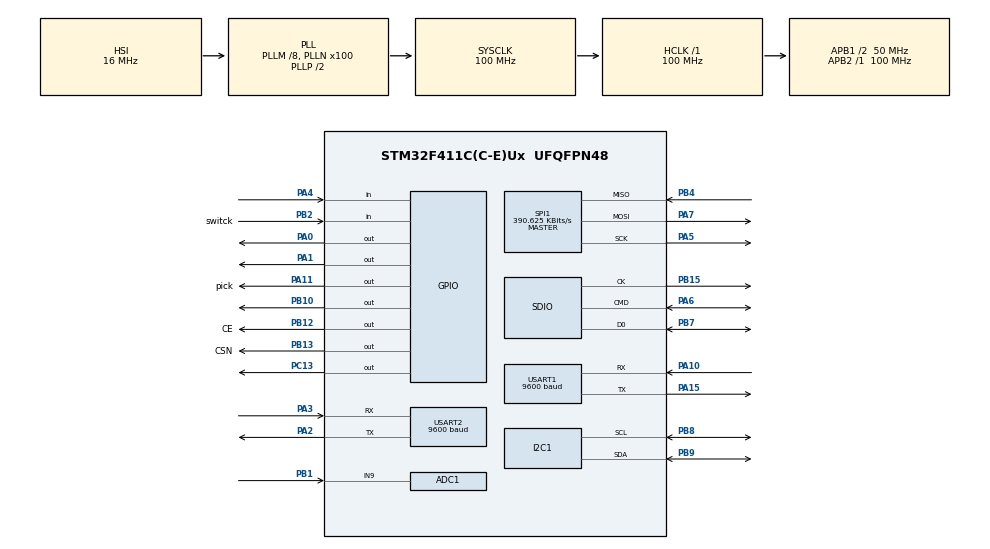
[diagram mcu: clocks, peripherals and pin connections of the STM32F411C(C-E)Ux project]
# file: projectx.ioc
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ADC1.Channel-2\#ChannelRegularConversion=ADC_CHANNEL_9
ADC1.NbrOfConversionFlag=1
ADC1.Rank-2\#ChannelRegularConversion=1
ADC1.SamplingTime-2\#ChannelRegularConversion=ADC_SAMPLETIME_3CYCLES
ADC1.master=1
Dma.Request0=SDIO_RX
Dma.Request1=SDIO_TX
Dma.SDIO_RX.0.Direction=DMA_PERIPH_TO_MEMORY
Dma.SDIO_RX.0.FIFOMode=DMA_FIFOMODE_ENABLE
Dma.SDIO_RX.0.FIFOThreshold=DMA_FIFO_THRESHOLD_FULL
Dma.SDIO_RX.0.Instance=DMA2_Stream3
Dma.SDIO_RX.0.MemBurst=DMA_MBURST_INC4
Dma.SDIO_RX.0.MemDataAlignment=DMA_MDATAALIGN_WORD
Dma.SDIO_RX.0.MemInc=DMA_MINC_ENABLE
Dma.SDIO_RX.0.Mode=DMA_PFCTRL
Dma.SDIO_RX.0.PeriphBurst=DMA_PBURST_INC4
Dma.SDIO_RX.0.PeriphDataAlignment=DMA_PDATAALIGN_WORD
Dma.SDIO_RX.0.PeriphInc=DMA_PINC_DISABLE
Dma.SDIO_RX.0.Priority=DMA_PRIORITY_LOW
Dma.SDIO_TX.1.Direction=DMA_MEMORY_TO_PERIPH
Dma.SDIO_TX.1.FIFOMode=DMA_FIFOMODE_ENABLE
Dma.SDIO_TX.1.FIFOThreshold=DMA_FIFO_THRESHOLD_FULL
Dma.SDIO_TX.1.Instance=DMA2_Stream6
Dma.SDIO_TX.1.MemBurst=DMA_MBURST_INC4
Dma.SDIO_TX.1.MemDataAlignment=DMA_MDATAALIGN_WORD
Dma.SDIO_TX.1.MemInc=DMA_MINC_ENABLE
Dma.SDIO_TX.1.Mode=DMA_PFCTRL
Dma.SDIO_TX.1.PeriphBurst=DMA_PBURST_INC4
Dma.SDIO_TX.1.PeriphDataAlignment=DMA_PDATAALIGN_WORD
Dma.SDIO_TX.1.PeriphInc=DMA_PINC_DISABLE
Dma.SDIO_TX.1.Priority=DMA_PRIORITY_LOW
FATFS._MAX_SS=4096
FATFS._USE_LFN=1
Mcu.Family=STM32F4
Mcu.Name=STM32F411C(C-E)Ux
Mcu.Package=UFQFPN48
NVIC.DMA2_Stream3_IRQn=true\:0\:0\:false\:false\:true\:false\:true\:true
NVIC.DMA2_Stream6_IRQn=true\:0\:0\:false\:false\:true\:false\:true\:true
NVIC.PriorityGroup=NVIC_PRIORITYGROUP_4
NVIC.USART1_IRQn=true\:0\:0\:false\:false\:true\:true\:false\:true
PA0-WKUP.Signal=GPIO_Output
PA1.Signal=GPIO_Output
PA10.Mode=Asynchronous
PA10.Signal=USART1_RX
PA11.GPIO_Label=pick
PA11.Signal=GPIO_Output
PA13.Mode=Serial_Wire
PA13.Signal=SYS_JTMS-SWDIO
PA14.Mode=Serial_Wire
PA14.Signal=SYS_JTCK-SWCLK
PA15.Mode=Asynchronous
PA15.Signal=USART1_TX
PA2.Mode=Asynchronous
PA2.Signal=USART2_TX
PA3.Mode=Asynchronous
PA3.Signal=USART2_RX
PA4.Signal=GPIO_Input
PA5.Mode=Full_Duplex_Master
PA5.Signal=SPI1_SCK
PA6.Mode=SD_1_bit
PA6.Signal=SDIO_CMD
PA7.Mode=Full_Duplex_Master
PA7.Signal=SPI1_MOSI
PB1.Signal=ADCx_IN9
PB10.Signal=GPIO_Output
PB12.GPIO_Label=CE
PB12.Signal=GPIO_Output
PB13.GPIO_Label=CSN
PB13.Signal=GPIO_Output
PB15.Mode=SD_1_bit
PB15.Signal=SDIO_CK
PB2.GPIO_Label=switck
PB2.Signal=GPIO_Input
PB4.Mode=Full_Duplex_Master
PB4.Signal=SPI1_MISO
PB7.Mode=SD_1_bit
PB7.Signal=SDIO_D0
PB8.Mode=I2C
PB8.Signal=I2C1_SCL
PB9.Mode=I2C
PB9.Signal=I2C1_SDA
PC13-ANTI_TAMP.Signal=GPIO_Output
ProjectManager.HeapSize=0x200
ProjectManager.StackSize=0x400
ProjectManager.TargetToolchain=STM32CubeIDE
RCC.48MHZClocksFreq_Value=40000000
RCC.AHBFreq_Value=100000000
RCC.APB1CLKDivider=RCC_HCLK_DIV2
RCC.APB1Freq_Value=50000000
RCC.APB1TimFreq_Value=100000000
RCC.APB2Freq_Value=100000000
RCC.APB2TimFreq_Value=100000000
RCC.CortexFreq_Value=100000000
RCC.HCLKFreq_Value=100000000
RCC.HSE_VALUE=25000000
RCC.HSI_VALUE=16000000
RCC.LSE_VALUE=32768
RCC.PLLM=8
RCC.PLLN=100
RCC.PLLQ=5
RCC.SYSCLKFreq_VALUE=100000000
RCC.SYSCLKSource=RCC_SYSCLKSOURCE_PLLCLK
RCC.VCOOutputFreq_Value=200000000
SDIO.ClockDiv=255
SDIO.HardwareFlowControl=SDIO_HARDWARE_FLOW_CONTROL_ENABLE
SH.ADCx_IN9.0=ADC1_IN9,IN9
SPI1.BaudRatePrescaler=SPI_BAUDRATEPRESCALER_256
SPI1.CalculateBaudRate=390.625 KBits/s
SPI1.Direction=SPI_DIRECTION_2LINES
SPI1.Mode=SPI_MODE_MASTER
SPI1.VirtualType=VM_MASTER
USART1.BaudRate=9600
USART1.VirtualMode=VM_ASYNC
USART2.BaudRate=9600
USART2.VirtualMode=VM_ASYNC
VP_FATFS_VS_SDIO.Mode=SDIO
board=custom

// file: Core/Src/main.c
/* USER CODE BEGIN Header */
/**
  ******************************************************************************
  * @file           : main.c
  * @brief          : Main program body
  ******************************************************************************
  * @attention
  *
  * Copyright (c) 2025 STMicroelectronics.
  * All rights reserved.
  *
  * This software is licensed under terms that can be found in the LICENSE file
  * in the root directory of this software component.
  * If no LICENSE file comes with this software, it is provided AS-IS.
  *
  ******************************************************************************
  */
/* USER CODE END Header */
#include "main.h"
#include "fatfs.h"

ADC_HandleTypeDef hadc1;

I2C_HandleTypeDef hi2c1;

SD_HandleTypeDef hsd;
DMA_HandleTypeDef hdma_sdio_rx;
DMA_HandleTypeDef hdma_sdio_tx;

SPI_HandleTypeDef hspi1;

UART_HandleTypeDef huart1;
UART_HandleTypeDef huart2;

void SystemClock_Config(void);
static void MX_GPIO_Init(void);
static void MX_DMA_Init(void);
static void MX_I2C1_Init(void);
static void MX_USART1_UART_Init(void);
static void MX_SPI1_Init(void);
static void MX_SDIO_SD_Init(void);
static void MX_ADC1_Init(void);
static void MX_USART2_UART_Init(void);

/* USER CODE BEGIN 0 */
void appmain();
/* USER CODE END 0 */

int main(void)
{

  /* MCU Configuration--------------------------------------------------------*/

  /* Reset of all peripherals, Initializes the Flash interface and the Systick. */
  HAL_Init();

  /* Configure the system clock */
  SystemClock_Config();

  /* Initialize all configured peripherals */
  MX_GPIO_Init();
  MX_DMA_Init();
  MX_I2C1_Init();
  MX_USART1_UART_Init();
  MX_SPI1_Init();
  MX_FATFS_Init();
  MX_SDIO_SD_Init();
  MX_ADC1_Init();
  MX_USART2_UART_Init();

  /* Infinite loop */
  /* USER CODE BEGIN WHILE */
  while (1)
  {
	  appmain();
    /* USER CODE END WHILE */

  }
}

void SystemClock_Config(void)
{
  RCC_OscInitTypeDef RCC_OscInitStruct = {0};
  RCC_ClkInitTypeDef RCC_ClkInitStruct = {0};

  /** Configure the main internal regulator output voltage
  */
  __HAL_RCC_PWR_CLK_ENABLE();
  __HAL_PWR_VOLTAGESCALING_CONFIG(PWR_REGULATOR_VOLTAGE_SCALE1);

  /** Initializes the RCC Oscillators according to the specified parameters
  * in the RCC_OscInitTypeDef structure.
  */
  RCC_OscInitStruct.OscillatorType = RCC_OSCILLATORTYPE_HSI;
  RCC_OscInitStruct.HSIState = RCC_HSI_ON;
  RCC_OscInitStruct.HSICalibrationValue = RCC_HSICALIBRATION_DEFAULT;
  RCC_OscInitStruct.PLL.PLLState = RCC_PLL_ON;
  RCC_OscInitStruct.PLL.PLLSource = RCC_PLLSOURCE_HSI;
  RCC_OscInitStruct.PLL.PLLM = 8;
  RCC_OscInitStruct.PLL.PLLN = 100;
  RCC_OscInitStruct.PLL.PLLP = RCC_PLLP_DIV2;
  RCC_OscInitStruct.PLL.PLLQ = 5;
  if (HAL_RCC_OscConfig(&RCC_OscInitStruct) != HAL_OK)
  {
    Error_Handler();
  }

  /** Initializes the CPU, AHB and APB buses clocks
  */
  RCC_ClkInitStruct.ClockType = RCC_CLOCKTYPE_HCLK|RCC_CLOCKTYPE_SYSCLK
                              |RCC_CLOCKTYPE_PCLK1|RCC_CLOCKTYPE_PCLK2;
  RCC_ClkInitStruct.SYSCLKSource = RCC_SYSCLKSOURCE_PLLCLK;
  RCC_ClkInitStruct.AHBCLKDivider = RCC_SYSCLK_DIV1;
  RCC_ClkInitStruct.APB1CLKDivider = RCC_HCLK_DIV2;
  RCC_ClkInitStruct.APB2CLKDivider = RCC_HCLK_DIV1;

  if (HAL_RCC_ClockConfig(&RCC_ClkInitStruct, FLASH_LATENCY_3) != HAL_OK)
  {
    Error_Handler();
  }
}

static void MX_ADC1_Init(void)
{

  ADC_ChannelConfTypeDef sConfig = {0};

  /** Configure the global features of the ADC (Clock, Resolution, Data Alignment and number of conversion)
  */
  hadc1.Instance = ADC1;
  hadc1.Init.ClockPrescaler = ADC_CLOCK_SYNC_PCLK_DIV4;
  hadc1.Init.Resolution = ADC_RESOLUTION_12B;
  hadc1.Init.ScanConvMode = DISABLE;
  hadc1.Init.ContinuousConvMode = DISABLE;
  hadc1.Init.DiscontinuousConvMode = DISABLE;
  hadc1.Init.ExternalTrigConvEdge = ADC_EXTERNALTRIGCONVEDGE_NONE;
  hadc1.Init.ExternalTrigConv = ADC_SOFTWARE_START;
  hadc1.Init.DataAlign = ADC_DATAALIGN_RIGHT;
  hadc1.Init.NbrOfConversion = 1;
  hadc1.Init.DMAContinuousRequests = DISABLE;
  hadc1.Init.EOCSelection = ADC_EOC_SINGLE_CONV;
  if (HAL_ADC_Init(&hadc1) != HAL_OK)
  {
    Error_Handler();
  }

  /** Configure for the selected ADC regular channel its corresponding rank in the sequencer and its sample time.
  */
  sConfig.Channel = ADC_CHANNEL_9;
  sConfig.Rank = 1;
  sConfig.SamplingTime = ADC_SAMPLETIME_3CYCLES;
  if (HAL_ADC_ConfigChannel(&hadc1, &sConfig) != HAL_OK)
  {
    Error_Handler();
  }

}

static void MX_I2C1_Init(void)
{

  hi2c1.Instance = I2C1;
  hi2c1.Init.ClockSpeed = 100000;
  hi2c1.Init.DutyCycle = I2C_DUTYCYCLE_2;
  hi2c1.Init.OwnAddress1 = 0;
  hi2c1.Init.AddressingMode = I2C_ADDRESSINGMODE_7BIT;
  hi2c1.Init.DualAddressMode = I2C_DUALADDRESS_DISABLE;
  hi2c1.Init.OwnAddress2 = 0;
  hi2c1.Init.GeneralCallMode = I2C_GENERALCALL_DISABLE;
  hi2c1.Init.NoStretchMode = I2C_NOSTRETCH_DISABLE;
  if (HAL_I2C_Init(&hi2c1) != HAL_OK)
  {
    Error_Handler();
  }

}

static void MX_SDIO_SD_Init(void)
{

  hsd.Instance = SDIO;
  hsd.Init.ClockEdge = SDIO_CLOCK_EDGE_RISING;
  hsd.Init.ClockBypass = SDIO_CLOCK_BYPASS_DISABLE;
  hsd.Init.ClockPowerSave = SDIO_CLOCK_POWER_SAVE_DISABLE;
  hsd.Init.BusWide = SDIO_BUS_WIDE_1B;
  hsd.Init.HardwareFlowControl = SDIO_HARDWARE_FLOW_CONTROL_ENABLE;
  hsd.Init.ClockDiv = 255;

}

static void MX_SPI1_Init(void)
{

  /* SPI1 parameter configuration*/
  hspi1.Instance = SPI1;
  hspi1.Init.Mode = SPI_MODE_MASTER;
  hspi1.Init.Direction = SPI_DIRECTION_2LINES;
  hspi1.Init.DataSize = SPI_DATASIZE_8BIT;
  hspi1.Init.CLKPolarity = SPI_POLARITY_LOW;
  hspi1.Init.CLKPhase = SPI_PHASE_1EDGE;
  hspi1.Init.NSS = SPI_NSS_SOFT;
  hspi1.Init.BaudRatePrescaler = SPI_BAUDRATEPRESCALER_256;
  hspi1.Init.FirstBit = SPI_FIRSTBIT_MSB;
  hspi1.Init.TIMode = SPI_TIMODE_DISABLE;
  hspi1.Init.CRCCalculation = SPI_CRCCALCULATION_DISABLE;
  hspi1.Init.CRCPolynomial = 10;
  if (HAL_SPI_Init(&hspi1) != HAL_OK)
  {
    Error_Handler();
  }

}

static void MX_USART1_UART_Init(void)
{

  huart1.Instance = USART1;
  huart1.Init.BaudRate = 9600;
  huart1.Init.WordLength = UART_WORDLENGTH_8B;
  huart1.Init.StopBits = UART_STOPBITS_1;
  huart1.Init.Parity = UART_PARITY_NONE;
  huart1.Init.Mode = UART_MODE_TX_RX;
  huart1.Init.HwFlowCtl = UART_HWCONTROL_NONE;
  huart1.Init.OverSampling = UART_OVERSAMPLING_16;
  if (HAL_UART_Init(&huart1) != HAL_OK)
  {
    Error_Handler();
  }

}

static void MX_USART2_UART_Init(void)
{

  huart2.Instance = USART2;
  huart2.Init.BaudRate = 9600;
  huart2.Init.WordLength = UART_WORDLENGTH_8B;
  huart2.Init.StopBits = UART_STOPBITS_1;
  huart2.Init.Parity = UART_PARITY_NONE;
  huart2.Init.Mode = UART_MODE_TX_RX;
  huart2.Init.HwFlowCtl = UART_HWCONTROL_NONE;
  huart2.Init.OverSampling = UART_OVERSAMPLING_16;
  if (HAL_UART_Init(&huart2) != HAL_OK)
  {
    Error_Handler();
  }

}

static void MX_DMA_Init(void)
{

  /* DMA controller clock enable */
  __HAL_RCC_DMA2_CLK_ENABLE();

  /* DMA interrupt init */
  /* DMA2_Stream3_IRQn interrupt configuration */
  HAL_NVIC_SetPriority(DMA2_Stream3_IRQn, 0, 0);
  HAL_NVIC_EnableIRQ(DMA2_Stream3_IRQn);
  /* DMA2_Stream6_IRQn interrupt configuration */
  HAL_NVIC_SetPriority(DMA2_Stream6_IRQn, 0, 0);
  HAL_NVIC_EnableIRQ(DMA2_Stream6_IRQn);

}

static void MX_GPIO_Init(void)
{
  GPIO_InitTypeDef GPIO_InitStruct = {0};

  /* GPIO Ports Clock Enable */
  __HAL_RCC_GPIOC_CLK_ENABLE();
  __HAL_RCC_GPIOA_CLK_ENABLE();
  __HAL_RCC_GPIOB_CLK_ENABLE();

  /*Configure GPIO pin Output Level */
  HAL_GPIO_WritePin(GPIOC, GPIO_PIN_13, GPIO_PIN_RESET);

  /*Configure GPIO pin Output Level */
  HAL_GPIO_WritePin(GPIOA, GPIO_PIN_0|GPIO_PIN_1|pick_Pin, GPIO_PIN_RESET);

  /*Configure GPIO pin Output Level */
  HAL_GPIO_WritePin(GPIOB, GPIO_PIN_10|CE_Pin|CSN_Pin, GPIO_PIN_RESET);

  /*Configure GPIO pin : PC13 */
  GPIO_InitStruct.Pin = GPIO_PIN_13;
  GPIO_InitStruct.Mode = GPIO_MODE_OUTPUT_PP;
  GPIO_InitStruct.Pull = GPIO_NOPULL;
  GPIO_InitStruct.Speed = GPIO_SPEED_FREQ_LOW;
  HAL_GPIO_Init(GPIOC, &GPIO_InitStruct);

  /*Configure GPIO pins : PA0 PA1 pick_Pin */
  GPIO_InitStruct.Pin = GPIO_PIN_0|GPIO_PIN_1|pick_Pin;
  GPIO_InitStruct.Mode = GPIO_MODE_OUTPUT_PP;
  GPIO_InitStruct.Pull = GPIO_NOPULL;
  GPIO_InitStruct.Speed = GPIO_SPEED_FREQ_LOW;
  HAL_GPIO_Init(GPIOA, &GPIO_InitStruct);

  /*Configure GPIO pin : PA4 */
  GPIO_InitStruct.Pin = GPIO_PIN_4;
  GPIO_InitStruct.Mode = GPIO_MODE_INPUT;
  GPIO_InitStruct.Pull = GPIO_NOPULL;
  HAL_GPIO_Init(GPIOA, &GPIO_InitStruct);

  /*Configure GPIO pin : switck_Pin */
  GPIO_InitStruct.Pin = switck_Pin;
  GPIO_InitStruct.Mode = GPIO_MODE_INPUT;
  GPIO_InitStruct.Pull = GPIO_NOPULL;
  HAL_GPIO_Init(switck_GPIO_Port, &GPIO_InitStruct);

  /*Configure GPIO pins : PB10 CE_Pin CSN_Pin */
  GPIO_InitStruct.Pin = GPIO_PIN_10|CE_Pin|CSN_Pin;
  GPIO_InitStruct.Mode = GPIO_MODE_OUTPUT_PP;
  GPIO_InitStruct.Pull = GPIO_NOPULL;
  GPIO_InitStruct.Speed = GPIO_SPEED_FREQ_LOW;
  HAL_GPIO_Init(GPIOB, &GPIO_InitStruct);

}

void Error_Handler(void)
{
  __disable_irq();
  while (1)
  {
  }
}
